VERSION ""

NS_ :

BS_:

BU_: XXX

BO_ 1680 Lights: 8 XXX
 SG_ NEW_SIGNAL_1 : 55|8@0+ (1,0) [0|255] "" XXX
 SG_ Lights status : 37|1@0+ (1,0) [0|15] "" XXX
 SG_ Reverse lights? : 43|1@1+ (1,0) [0|255] "" XXX

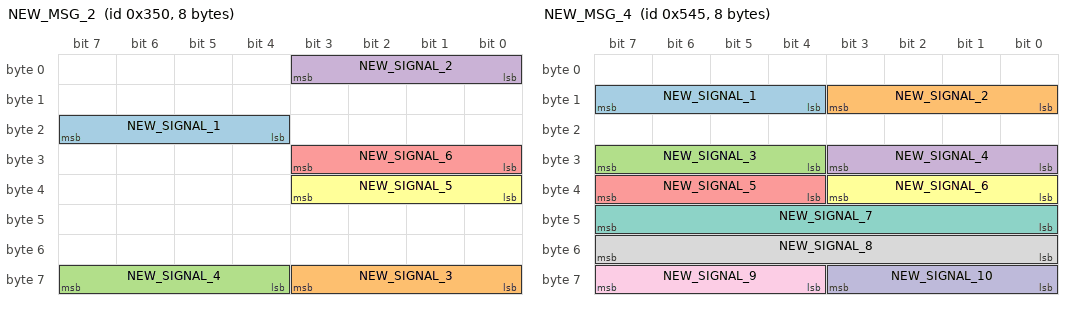
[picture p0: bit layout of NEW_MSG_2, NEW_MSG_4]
BO_ 848 NEW_MSG_2: 8 XXX
 SG_ NEW_SIGNAL_1 : 23|4@0+ (1,0) [0|15] "" XXX
 SG_ NEW_SIGNAL_3 : 56|4@1+ (1,0) [0|15] "" XXX
 SG_ NEW_SIGNAL_4 : 63|4@0+ (1,0) [0|15] "" XXX
 SG_ NEW_SIGNAL_2 : 0|4@1+ (1,0) [0|15] "" XXX
 SG_ NEW_SIGNAL_6 : 24|4@1+ (1,0) [0|15] "" XXX
 SG_ NEW_SIGNAL_5 : 35|4@0+ (1,0) [0|15] "" XXX

BO_ 544 NEW_MSG_3: 8 XXX
 SG_ NEW_SIGNAL_2 : 0|4@1+ (1,0) [0|15] "" XXX
 SG_ NEW_SIGNAL_1 : 8|4@1+ (1,0) [0|255] "" XXX
 SG_ NEW_SIGNAL_3 : 15|1@0+ (1,0) [0|7] "" XXX
 SG_ NEW_SIGNAL_4 : 23|8@0+ (1,0) [0|15] "" XXX
 SG_ NEW_SIGNAL_6 : 48|16@1+ (1,0) [0|255] "" XXX
 SG_ NEW_SIGNAL_5 : 55|16@0+ (1,0) [0|15] "" XXX
 SG_ NEW_SIGNAL_7 : 32|8@1+ (1,0) [0|255] "" XXX

BO_ 1349 NEW_MSG_4: 8 XXX
 SG_ NEW_SIGNAL_1 : 15|4@0+ (1,0) [0|15] "" XXX
 SG_ NEW_SIGNAL_2 : 8|4@1+ (1,0) [0|15] "" XXX
 SG_ NEW_SIGNAL_3 : 31|4@0+ (1,0) [0|255] "" XXX
 SG_ NEW_SIGNAL_4 : 24|4@1+ (1,0) [0|15] "" XXX
 SG_ NEW_SIGNAL_5 : 39|4@0+ (1,0) [0|15] "" XXX
 SG_ NEW_SIGNAL_6 : 32|4@1+ (1,0) [0|15] "" XXX
 SG_ NEW_SIGNAL_7 : 40|8@1+ (1,0) [0|255] "" XXX
 SG_ NEW_SIGNAL_8 : 48|8@1+ (1,0) [0|255] "" XXX
 SG_ NEW_SIGNAL_9 : 60|4@1+ (1,0) [0|255] "" XXX
 SG_ NEW_SIGNAL_10 : 56|4@1+ (1,0) [0|15] "" XXX

BO_ 356 NEW_MSG_5: 8 XXX
 SG_ NEW_SIGNAL_1 : 48|8@1+ (1,0) [0|15] "" XXX
 SG_ NEW_SIGNAL_2 : 56|8@1+ (1,0) [0|15] "" XXX

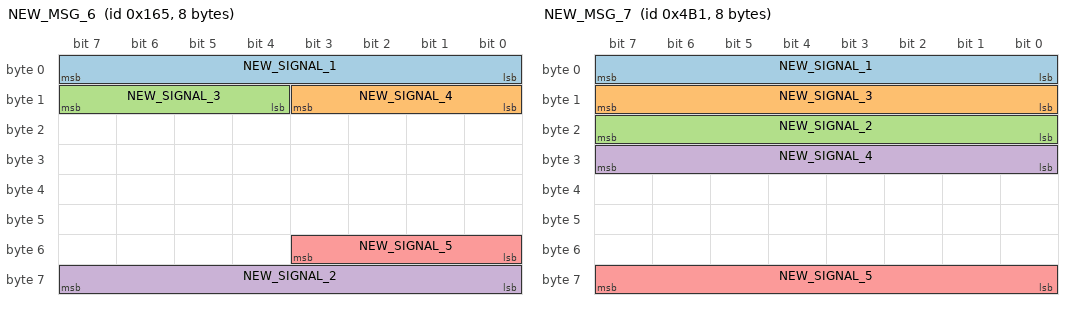
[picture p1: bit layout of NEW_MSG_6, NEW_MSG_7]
BO_ 357 NEW_MSG_6: 8 XXX
 SG_ NEW_SIGNAL_1 : 7|8@0+ (1,0) [0|15] "" XXX
 SG_ NEW_SIGNAL_4 : 8|4@1+ (1,0) [0|15] "" XXX
 SG_ NEW_SIGNAL_3 : 15|4@0+ (1,0) [0|15] "" XXX
 SG_ NEW_SIGNAL_2 : 63|8@0+ (1,0) [0|255] "" XXX
 SG_ NEW_SIGNAL_5 : 51|4@0+ (1,0) [0|255] "" XXX

BO_ 1201 NEW_MSG_7: 8 XXX
 SG_ NEW_SIGNAL_1 : 7|8@0+ (1,0) [0|15] "" XXX
 SG_ NEW_SIGNAL_3 : 15|8@0+ (1,0) [0|255] "" XXX
 SG_ NEW_SIGNAL_2 : 16|8@1+ (1,0) [0|255] "" XXX
 SG_ NEW_SIGNAL_4 : 24|8@1+ (1,0) [0|255] "" XXX
 SG_ NEW_SIGNAL_5 : 56|8@1+ (1,0) [0|255] "" XXX

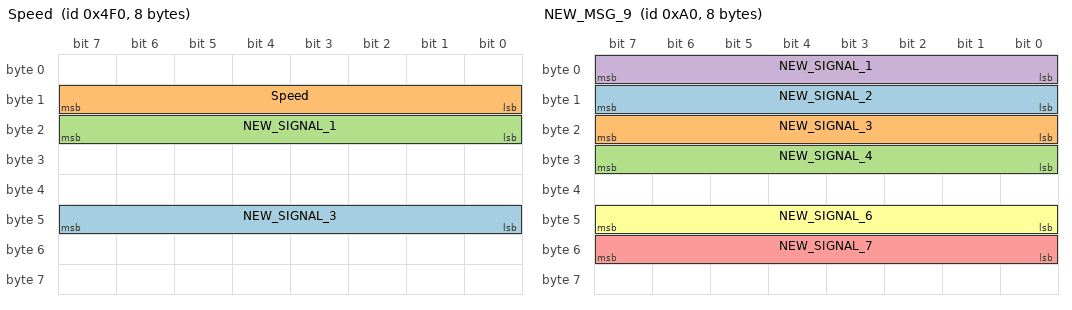
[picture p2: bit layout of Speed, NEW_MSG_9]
BO_ 1264 Speed: 8 XXX
 SG_ NEW_SIGNAL_3 : 40|8@1+ (1,0) [0|63] "" XXX
 SG_ Speed : 8|8@1+ (1,0) [0|15] "" XXX
 SG_ NEW_SIGNAL_1 : 23|8@0+ (1,0) [0|255] "" XXX

BO_ 160 NEW_MSG_9: 8 XXX
 SG_ NEW_SIGNAL_2 : 8|8@1+ (1,0) [0|255] "" XXX
 SG_ NEW_SIGNAL_3 : 16|8@1+ (1,0) [0|255] "" XXX
 SG_ NEW_SIGNAL_4 : 24|8@1+ (1,0) [0|255] "" XXX
 SG_ NEW_SIGNAL_1 : 7|8@0+ (1,0) [0|255] "" XXX
 SG_ NEW_SIGNAL_7 : 48|8@1+ (1,0) [0|255] "" XXX
 SG_ NEW_SIGNAL_6 : 40|8@1+ (1,0) [0|255] "" XXX

BO_ 339 NEW_MSG_10: 8 XXX
 SG_ NEW_SIGNAL_1 : 55|8@0+ (1,0) [0|15] "" XXX
 SG_ NEW_SIGNAL_2 : 56|8@1+ (1,0) [0|255] "" XXX

BO_ 399 NEW_MSG_11: 8 XXX
 SG_ NEW_SIGNAL_1 : 40|8@1+ (1,0) [0|255] "" XXX
 SG_ NEW_SIGNAL_2 : 48|8@1+ (1,0) [0|255] "" XXX

BO_ 608 NEW_MSG_12: 8 XXX
 SG_ NEW_SIGNAL_1 : 8|8@1+ (1,0) [0|255] "" XXX
 SG_ NEW_SIGNAL_2 : 16|8@1+ (1,0) [0|255] "" XXX

BO_ 1072 NEW_MSG_1: 8 XXX
 SG_ NEW_SIGNAL_1 : 15|4@0+ (1,0) [0|255] "" XXX
 SG_ NEW_SIGNAL_2 : 48|4@1+ (1,0) [0|255] "" XXX

BO_ 497 NEW_MSG_8: 8 XXX
 SG_ NEW_SIGNAL_1 : 23|16@0+ (1,0) [0|65535] "" XXX
 SG_ NEW_SIGNAL_2 : 39|16@0+ (1,0) [0|65535] "" XXX
 SG_ NEW_SIGNAL_3 : 55|16@0+ (1,0) [0|65535] "" XXX

BO_ 790 Also speed?: 8 XXX
 SG_ NEW_SIGNAL_1 : 7|8@0+ (1,0) [0|65535] "" XXX
 SG_ NEW_SIGNAL_2 : 15|16@0+ (1,0) [0|255] "" XXX
 SG_ NEW_SIGNAL_3 : 31|16@0+ (1,0) [0|65535] "" XXX
 SG_ NEW_SIGNAL_4 : 47|8@0+ (1,0) [0|65535] "" XXX
 SG_ Also speed? : 55|8@0+ (1,0) [0|255] "" XXX

BO_ 161 NEW_MSG_13: 8 XXX
 SG_ NEW_SIGNAL_1 : 7|8@0+ (1,0) [0|255] "" XXX
 SG_ NEW_SIGNAL_2 : 39|8@0+ (1,0) [0|255] "" XXX

CM_ SG_ 1264 Speed "Speed";
